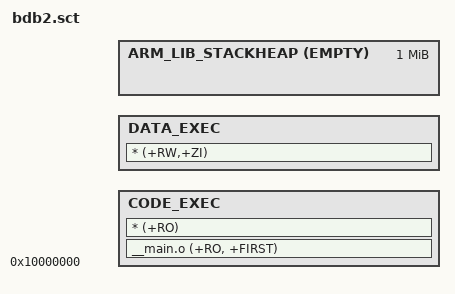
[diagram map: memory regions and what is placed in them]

RAM_LOAD 0x10000000 0x3d00000
{
    CODE_EXEC +0
    {
        __main.o (+RO, +FIRST)
        * (+RO)
    }

    DATA_EXEC +0
    {
        * (+RW,+ZI)
    }

    ARM_LIB_STACKHEAP +0 EMPTY 0x100000
    {
    }
}
